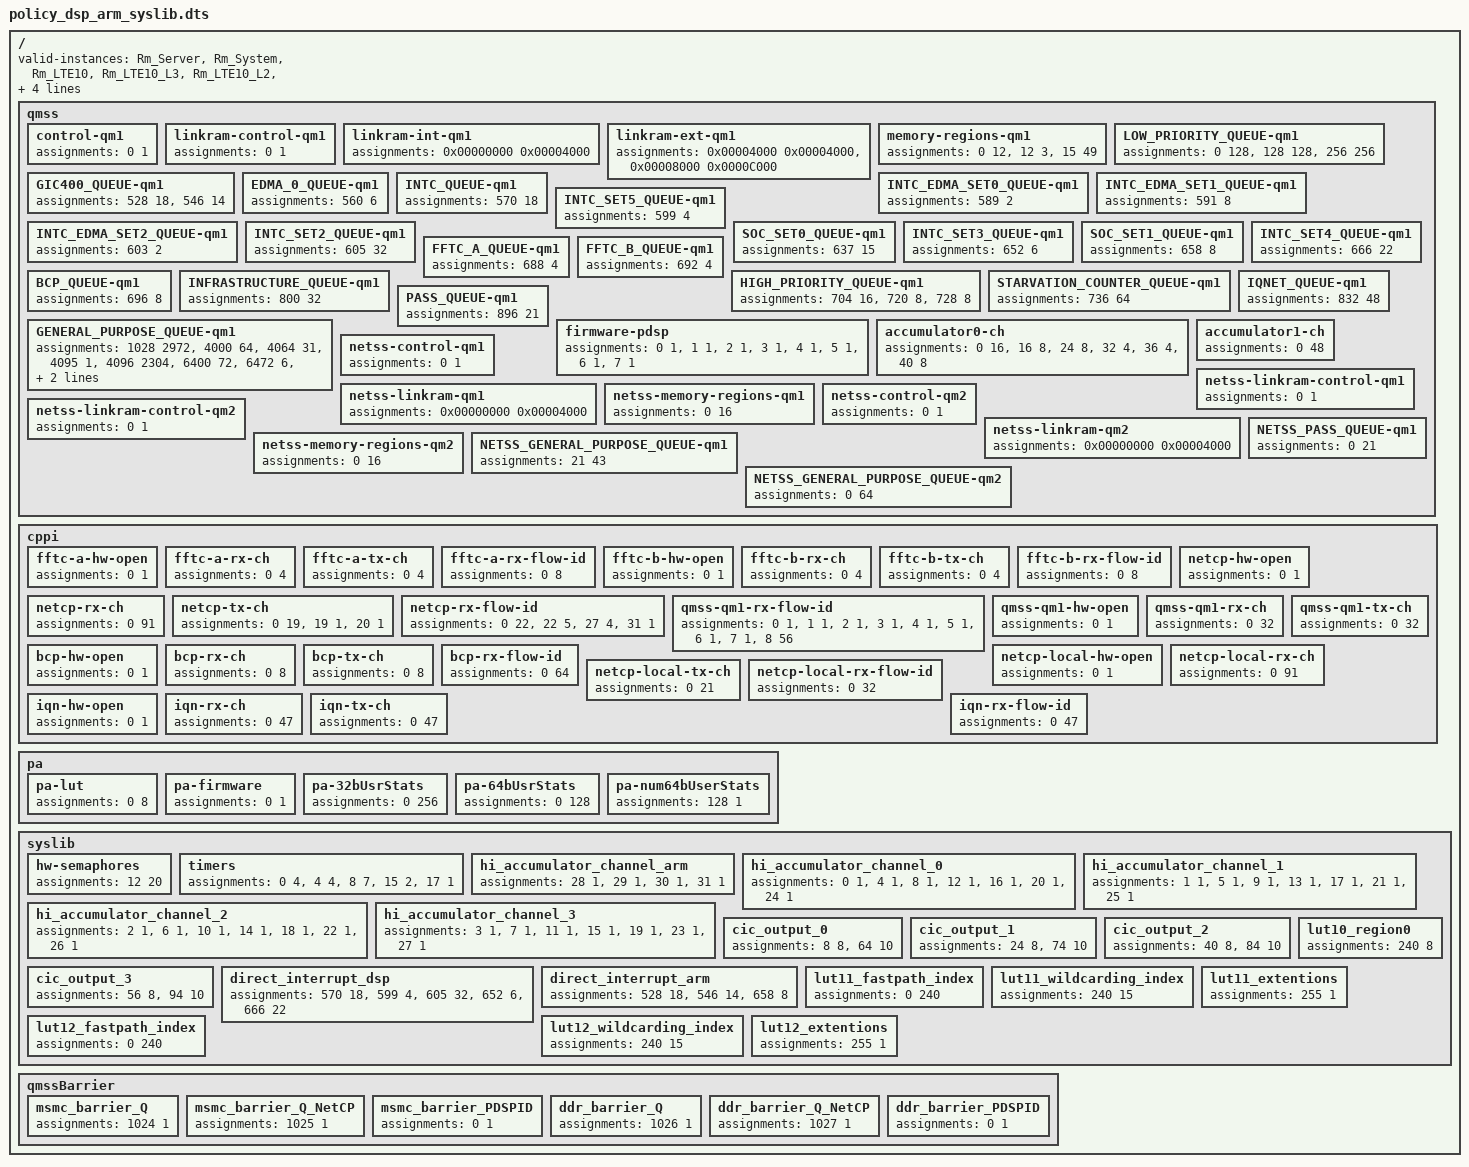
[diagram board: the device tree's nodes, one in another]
/dts-v1/;

/* Keystone II policy containing reserving resources used by Linux Kernel */

/ {
    /* Valid instance list contains instance names used within TI example projects
     * utilizing RM.  The list can be modified as needed by applications integrating
     * RM.  For an RM instance to be given permissions the name used to initialize it
     * must be present in this list */
    valid-instances = "Rm_Server",
                      "Rm_System",
                      "Rm_LTE10",
                      "Rm_LTE10_L3",
                      "Rm_LTE10_L2",
                      "Rm_LTE10_L2A",
                      "Rm_LTE10_L2B",
                      "Rm_LTE10_L1A",
                      "Rm_LTE10_L1B",
                      "Rm_LTE9A",
                      "Rm_LTE9A_L1",
                      "Rm_LTE9A_L2",
                      "Rm_LTE9B",
                      "Rm_LTE9B_L1",
                      "Rm_LTE9B_L2";
    qmss {
        control-qm1 {
            assignments = <0 1>, "iu = (*)";
        };

        linkram-control-qm1 {
            assignments = <0 1>, "(*)";             /* Used by Kernel */
        };

        linkram-int-qm1 {
            assignments = <0x00000000 0x00004000>, "iu = (*)";
        };
        linkram-ext-qm1 {
            /* linux provided 0x14000 descriptors of linking RAM but uses 0x4000 to 0x8000 */
            assignments = <0x00004000 0x00004000>, "(*)", /* used by Kernel */
                          <0x00008000 0x0000C000>, "iu = (*)";
        };

        memory-regions-qm1 {
            assignments = <0  12>, "iu = (*)",
                          <12 3>,  "(*)",             /* Used by Kernel */
                          <15 49>, "iu = (*)";
        };

        LOW_PRIORITY_QUEUE-qm1 {
            /* this is loosely coupled with accumulator-ch channels 32-47.  These queues are
             * just suggested to be paired with these channels, the accumulator can be sw
             * configured to use any queue */
            assignments = <0 128>,   "iu = (*)", /* suggested for channels 32-35 */
                          <128 128>, "     (*)", /* used by linux (accumulator-low-#); linux pairs these to channels 36-39 */
                          <256 256>, "iu = (*)"; /* suggested for channels 40-47 */
        };
        GIC400_QUEUE-qm1 {
            assignments = <528 18>,   "(*)",            /* Used by Kernel */
                          <546 14>,   "iu = (*)";
        };
        EDMA_0_QUEUE-qm1 {
            assignments = <560 6>, "iu = (*)";
        };
        INTC_QUEUE-qm1 {
            assignments = <570 18>, "iu = (*)";           /* Used by Kernel and DSP */
        };
        INTC_EDMA_SET0_QUEUE-qm1 {
            assignments = <589 2>,  "iu = (*)";
        };
        INTC_EDMA_SET1_QUEUE-qm1 {
            assignments = <591 8>,  "iu = (*)";
        };
        INTC_SET5_QUEUE-qm1 {
            assignments = <599 4>,  "iu = (*)";
        };
        INTC_EDMA_SET2_QUEUE-qm1 {
            assignments = <603 2>,  "iu = (*)";
        };
        INTC_SET2_QUEUE-qm1 {
            assignments = <605 32>, "iu = (*)";
        };
        SOC_SET0_QUEUE-qm1 {
            assignments = <637 15>, "iu = (*)";
        };
        INTC_SET3_QUEUE-qm1 {
            assignments = <652 6>,  "iu = (*)";
        };
        SOC_SET1_QUEUE-qm1 {
            assignments = <658 8>, "iu = (*)";
        };
        INTC_SET4_QUEUE-qm1 {
            assignments = <666 22>, "iu = (*)";
        };
        FFTC_A_QUEUE-qm1 {
            assignments = <688 4>, "iu = (*)";
        };
        FFTC_B_QUEUE-qm1 {
            assignments = <692 4>, "iu = (*)";
        };
        BCP_QUEUE-qm1 {
            assignments = <696 8>, "iu = (*)";
        };
        HIGH_PRIORITY_QUEUE-qm1 {
            /* this is loosely coupled with accumulator-ch channels 0-15.  These queues are
             * just suggested to be paired with these channels, the accumulator can be sw
             * configured to use any queue */
            assignments = <704 16>, "iu = (*)", /* suggested for channels 0-15 */
                          <720 8>,  "iu = (*)", /* Declared, but not used, by linux (accumulator-high.values). */
                          <728 8>,  "iu = (*)"; /* suggested for channels 24-31 */
        };
        STARVATION_COUNTER_QUEUE-qm1 {
            assignments = <736 64>, "iu = (*)";
        };
        INFRASTRUCTURE_QUEUE-qm1 {
            assignments = <800  32>,   "iu = (*)";
        };
        IQNET_QUEUE-qm1 {
            assignments = <832 48>, "iu = (*)";
        };
        PASS_QUEUE-qm1 {
            assignments = <896 21>, "iu = (*)";       /* used by both kernel and DSP */
        };
        GENERAL_PURPOSE_QUEUE-qm1 {
            assignments = /* First 4 queues are reserved for QMSS barrier */
                          /*<1024 4>,     "iu = (Rm_System)",*/
                          <1028 2972>,  "iu = (*)",
                          <4000 64>,    "(*)",       /* Used by Kernel */
                          <4064 31>,    "iu = (*)",
                          <4095 1>,     "iue = (*)",   /* Queues ending in 0xfff can't be used as return queue (hw reserved) */
                          <4096 2304>,  "iu = (*)",

                          /* 6400-6477 is taken by linux for qostree2, but DSP can transmit via "fastpath" queues */
                          <6400 72>,    "u = (*)",   /* qos queues for DSP (fastpath-best-effort, fastpath-hp, 4g-cos#, 3g-cos#, wifi-cos#) use (open by number) not init */
                          <6472 6>,     "(*)",       /* qos queues for linux (linux-best-effort, linux-cos#, linux-hp) - DSP can't use */
                          <6478 114>,   "(*)",       /* unconfigured QoS/Linux queues (qos-inputs-2) */

                          <6592 1408>,  "iu = (*)",

                          /* 8000-8191 is taken by linux for qostree but DSP can transmit via "fastpath" queues */
                          <8000 72>,    "u = (*)",   /* qos queues for DSP (fastpath-best-effort, fastpath-hp, 4g-cos#, 3g-cos#, wifi-cos#) use (open by number) not init */
                          <8072 6>,     "(*)",       /* qos queues for linux (linux-best-effort, linux-cos#, linux-hp) - DSP can't use */
                          <8078 114>,   "(*)";       /* unconfigured QoS/Linux queues (qos-inputs-1) */
                                                     /* note for q 8191: Queues ending in 0xfff can't be used as return queue (hw reserved) */
        };

        firmware-pdsp {
            assignments = <0 1>, "     (*)", /* pdsp0: accumulator 0 downloaded by linux */
                          <1 1>, "iu = (*)", /* pdsp1: for em scheduler if event machine is used (not downloaded by linux) */
                          <2 1>, "iu = (Rm_System)", /* pdsp2: for accumulator 1 on second intd (not downloaded by linux) */
                          <3 1>, "     (*)", /* pdsp3: qostree downloaded by linux */
                          <4 1>, "iu = (*)", /* pdsp4: for em scheduler if event machine is used (not downloaded by linux) */
                          <5 1>, "iu = (*)", /* pdsp5: for em scheduler if event machine is used (not downloaded by linux) */
                          <6 1>, "iu = (*)", /* pdsp6: for em router if event machine is used (not downloaded by linux) */
                          <7 1>, "     (*)"; /* pdsp7: qostree2 downloaded by linux */
        };
        accumulator0-ch { /* accumulator using first INTD */
            assignments = <0 16>, "iu = (*)",    /* high priority 0-15 available for everyone */
                          <16 8>, "iu = (*)",    /* declared but not used by linux, subject to change */
                          <24 8>, "iu = (*)",    /* last 8 high priority are used by event machine, available in non EM use case */
                          <32 4>, "iu = (*)",    /* first 4 low priority are used by event machine, available in non EM use case */
                          <36 4>, "     (*)",    /* next 4 low priority are used by linux (accumulator-low-#) */
                          <40 8>, "iu = (*)";    /* available for all */
        };
        accumulator1-ch { /* accumulator using second INTD */
            assignments = <0 48>, "iu = (*)";    /* linux doesn't use it */
        };

        netss-control-qm1 {
            assignments = <0 1>, "iu = (*)";
        };
        netss-linkram-control-qm1 {
            assignments = <0 1>, "iu = (*)";
        };
        netss-linkram-qm1 {
            assignments = <0x00000000 0x00004000>, "iu = (*)";
        };
        netss-memory-regions-qm1 {
            assignments = <0 16>, "iu = (*)";
        };

        netss-control-qm2 {
            assignments = <0 1>, "iu = (*)";
        };
        netss-linkram-control-qm2 {
            assignments = <0 1>, "iu = (*)";
        };
        netss-linkram-qm2 {
            assignments = <0x00000000 0x00004000>, "iu = (*)";
        };
        netss-memory-regions-qm2 {
            assignments = <0 16>, "iu = (*)";
        };

        NETSS_PASS_QUEUE-qm1 {
            assignments = <0 21>, "iu = (*)";
        };
        NETSS_GENERAL_PURPOSE_QUEUE-qm1 {
            assignments = <21 43>, "iu = (*)";
        };
        NETSS_GENERAL_PURPOSE_QUEUE-qm2 {
            assignments = <0 64>, "iu = (*)";
        };
    }; /* qmss */

    cppi {
        fftc-a-hw-open {
            assignments = <0 1>, "iu = (*)";
        };
        fftc-a-rx-ch {
            assignments = <0 4>, "iu = (*)";
        };
        fftc-a-tx-ch {
            assignments = <0 4>, "iu = (*)";
        };
        fftc-a-rx-flow-id {
            assignments = <0 8>, "iu = (*)";
        };   

        fftc-b-hw-open {
            assignments = <0 1>, "iu = (*)";
        };
        fftc-b-rx-ch {
            assignments = <0 4>, "iu = (*)";
        };
        fftc-b-tx-ch {
            assignments = <0 4>, "iu = (*)";
        };
        fftc-b-rx-flow-id {
            assignments = <0 8>, "iu = (*)";
        };   

        netcp-hw-open {
            assignments = <0 1>, "iu = (*)";
        };
        netcp-rx-ch {
            assignments = <0 91>, "     (*)"; /* initialized by kernel */
        };
        netcp-tx-ch {
            assignments = <0  19>, "     (*)", /* initialized by kernel, can directly open queuse */
                          <19  1>, "iu = (*)", /* SA channel.  Linux initializes, but some applications need to enable/disable on fly */
                          <20  1>, "     (*)"; /* initialized by kernel, can directly open queuse */

        };
        netcp-rx-flow-id {
            assignments = <0 22>, "iu = (*)", /* available */
                          <22 5>, "     (*)", /* used by kernel (netrx0, netrx1, netrx2, netrx3, crypto-rx0) */
                          <27 4>, "iu = (*)", /* available */
                          <31 1>, "(*)";      /* Used by kernel - parx */
        };

        /*****************************************************************************************
         * NOTE: The name proxy(s) for DSP-ARM communication reserves 2 sets of infrastructure
         * resources which are required used by the agent server in each realm.
         *
         * LTE9A RAT ARM Name Proxy resource usage
         *    Local Flow Id  0 :
         *    Rx Channel     0 :
         *    Tx Channel     1 :
         *
         * LTE9A RAT DSP Name Proxy resource usage
         *    Local Flow Id  1 :
         *    Rx Channel     1 :
         *    Tx Channel     0 :
         *
         * LTE9A RAT ARM Name Proxy resource usage
         *    Local Flow Id  2 :
         *    Rx Channel     2 :
         *    Tx Channel     3 :
         *
         * LTE9A RAT DSP Name Proxy resource usage
         *    Local Flow Id  3 :
         *    Rx Channel     3 :
         *    Tx Channel     2 :
         *
         * It is assumed that the name proxy in the DSP is executing in the L2 domain. If this is
         * not the case please change the RM client name accordingly.
         *
         * For the Release 10; the name proxy will execute on the DSP in the L1 domain. The L2 domain
         * whether it executes on DSP/ARM will also execute the name proxy. There could be 2 L2
         * domains L2A handling L1A and L2B handling L2B.
         *
         * The convention is that Flow Id 0, 2, 4, 6 are always used by the SYSLIB servers.
         * Flow Id 1, 3, 5, 7 are available to the applications.
         ********************************************************************************************/
        qmss-qm1-rx-flow-id {
            assignments = <0 1>,  "iu = (Rm_LTE9A Rm_LTE10)",
                          <1 1>,  "iu = (Rm_LTE9A_L2 Rm_LTE10_L1A)",
                          <2 1>,  "iu = (Rm_LTE9B Rm_LTE10)",
                          <3 1>,  "iu = (Rm_LTE9B_L2 Rm_LTE10_L1B)",
                          <4 1>,  "iu = (Rm_LTE10)",
                          <5 1>,  "iu = (Rm_LTE10_L2A)",
                          <6 1>,  "iu = (Rm_LTE10)",
                          <7 1>,  "iu = (Rm_LTE10_L2B)",
                          <8 56>, "iu = (*)";
        };
        qmss-qm1-hw-open {
            assignments = <0 1>, "iu = (*)";
        };
        qmss-qm1-rx-ch {
            assignments = <0 32>, "iu = (*)";
        };
        qmss-qm1-tx-ch {
            assignments = <0 32>, "iu = (*)";
        };

        bcp-hw-open {
            assignments = <0 1>, "iu = (*)";
        };
        bcp-rx-ch {
            assignments = <0 8>, "iu = (*)";
        };
        bcp-tx-ch {
            assignments = <0 8>, "iu = (*)";
        };
        bcp-rx-flow-id {
            assignments = <0 64>, "iu = (*)";
        };
        
        netcp-local-hw-open {
            assignments = <0 1>, "iu = (*)";
        };
        netcp-local-rx-ch {
            assignments = <0 91>, "iu = (*)";
        };
        netcp-local-tx-ch {
            assignments = <0 21>, "iu = (*)";
        };
        netcp-local-rx-flow-id {
            assignments = <0 32>, "iu = (*)";
        };

        iqn-hw-open {
            assignments = <0 1>, "iu = (*)";
        };
        iqn-rx-ch {
            assignments = <0 47>, "iu = (*)";
        };
        iqn-tx-ch {
            assignments = <0 47>, "iu = (*)";
        };
        iqn-rx-flow-id {
            assignments = <0 47>, "iu = (*)";
        };
    }; /* cppi */

    pa {
        pa-lut {
            assignments = <0 8>, "iu = (*)";
        };
        pa-firmware {
            assignments = <0 1>, "(*)"; /* linux downloads PA firmware */
        };
        pa-32bUsrStats {
            assignments = <0 256>, "iu = (*)";
        };
        pa-64bUsrStats {
            assignments = <0 128>, "iu = (*)";
        };
        pa-num64bUserStats {
            assignments = <128 1>, "iu = (*)";
        };
    }; /* pa */

    syslib {
        /*****************************************************************************
         * Hardware semaphores:
         *  - All hardware semaphores are assigned to all the RM instances
         *****************************************************************************/
        hw-semaphores {
            assignments = <12 20>, "iu = (*)";
        };

        /*****************************************************************************
         * Hardware timers:
         *  - Assign the hardware timers to the all RM instances.
         *  - Each DSP core executing BIOS will take 1 timer.
         *  - Timer 15 is taken up by the Linux kernel.
         *****************************************************************************/
        timers {
            assignments = <0  4>,  "     (*)", /* used by BIOS kernel on DSP cores */
                          <4  4>,  "     (*)", /* These are not available on K2L */
                          <8  7>,  "iu = (*)", /* available */
                          <15 2>,  "     (*)", /* used by kernel */
                          <17 1>,  "iu = (*)"; /* available */
        };

        /*****************************************************************************
         * High Priority accumulated channels:
         *  - Each core has 7 assigned channels each of which is available to all the
         *    RM instances.
         *  - ARM has 4 accumulated channels allocated for its use
         *****************************************************************************/
        hi_accumulator_channel_arm {
            assignments =   <28 1>, "iu = (*)",
                            <29 1>, "iu = (*)",
                            <30 1>, "iu = (*)",
                            <31 1>, "iu = (*)";
        };
        hi_accumulator_channel_0 {
            assignments =   <0  1>, "iu = (*)",
                            <4  1>, "iu = (*)",
                            <8  1>, "iu = (*)",
                            <12 1>, "iu = (*)",
                            <16 1>, "iu = (*)",
                            <20 1>, "iu = (*)",
                            <24 1>, "iu = (*)";
        };
        hi_accumulator_channel_1 {
            assignments =   <1  1>, "iu = (*)",
                            <5  1>, "iu = (*)",
                            <9  1>, "iu = (*)",
                            <13 1>, "iu = (*)",
                            <17 1>, "iu = (*)",
                            <21 1>, "iu = (*)",
                            <25 1>, "iu = (*)";
        };
        hi_accumulator_channel_2 {
            assignments =   <2  1>, "iu = (*)",
                            <6  1>, "iu = (*)",
                            <10 1>, "iu = (*)",
                            <14 1>, "iu = (*)",
                            <18 1>, "iu = (*)",
                            <22 1>, "iu = (*)",
                            <26 1>, "iu = (*)";
        };
        hi_accumulator_channel_3 {
            assignments =   <3  1>, "iu = (*)",
                            <7  1>, "iu = (*)",
                            <11 1>, "iu = (*)",
                            <15 1>, "iu = (*)",
                            <19 1>, "iu = (*)",
                            <23 1>, "iu = (*)",
                            <27 1>, "iu = (*)";
        };

        /*****************************************************************************
         * System Interrupt Mappings:
         *  - Each system interrupt on each is available to all RM instances.
         *****************************************************************************/
        cic_output_0 {
            assignments = <8  8>  , "iu = (*)",
                          <64 10> , "iu = (*)";
        };
        cic_output_1 {
            assignments = <24 8>  , "iu = (*)",
                          <74 10> , "iu = (*)";
        };
        cic_output_2 {
            assignments = <40 8>  , "iu = (*)",
                          <84 10> , "iu = (*)";
        };
        cic_output_3 {
            assignments = <56 8>  , "iu = (*)",
                          <94 10> , "iu = (*)";
        };

        /*****************************************************************************
         * Direct Interrupt Mappings:
         *  - On the DSP all the direct interrupt queues are available to all RM
         *    instances
         *  - On ARM however we need to be careful since the GIC queues are also used
         *    by the Linux kernel; so any changes in the GIC queue assignments would
         *    need to be aligned with the kernel DTB file also.
         *  - SOC-SET1 is shared but currently has been allocated to ARM
         *****************************************************************************/
        direct_interrupt_dsp {
            assignments = <570  18>  , "iu = (*)",
                          <599  4>   , "iu = (*)",
                          <605  32>  , "iu = (*)",
                          <652  6>   , "iu = (*)",
                          <666  22>  , "iu = (*)";
        };
        direct_interrupt_arm {
            assignments = <528  18> , "     (*)",    /* Used by the Linux kernel. */
                          <546  14> , "iu = (*)",
                          <658  8>  , "iu = (*)";
        };

        /*****************************************************************************
         * LUT1-0 entries for Ethernet Rules
         ****************************************************************************/
        lut10_region0 {
            assignments = <240 8>, "iu = (*)";
        };

        /*****************************************************************************
         * LUT1 entries
         * - The following section defines how LUT1 entries will be used in fast path
         *   creation
         * - There are 3 groups for both LUT1-1 and LUT1-2
         *   1. Normal Fast Path
         *   2. Wild Carding Fast Path
         *   3. LUT Extension
         *****************************************************************************/
        /* LUT1-1 */
        lut11_fastpath_index {
            assignments = <0 240>, "iu = (*)";
        };
        lut11_wildcarding_index {
            assignments = <240 15>, "iu = (*)";
        };
        lut11_extentions {
            assignments = <255 1>, "     (*)";    /* Reserved */
        };

        /* LUT1-2 */
        lut12_fastpath_index {
            assignments = <0 240>, "iu = (*)";
        };
        lut12_wildcarding_index {
            assignments = <240 15>, "iu = (*)";
        };
        lut12_extentions {
            assignments = <255 1>, "     (*)";    /* Reserved */
        };
    }; /* syslib */

    qmssBarrier {
        msmc_barrier_Q {
            assignments = <1024 1>, "iu = (Rm_System)";  /* QMSS MSMC Barrier Queues */
        };
        msmc_barrier_Q_NetCP {
            assignments = <1025 1>, "iu = (Rm_System)";  /* QMSS MSMC Barrier Queues */
        };
        msmc_barrier_PDSPID {
            assignments = <0 1>, "iu = (Rm_System)";    /* QMSS MSMC Barrier PDSP ID */
        };
        ddr_barrier_Q {
            assignments = <1026 1>, "iu = (Rm_System)";  /* QMSS DDR Barrier Queues */
        };
        ddr_barrier_Q_NetCP {
            assignments = <1027 1>, "iu = (Rm_System)";  /* QMSS DDR Barrier Queues */
        };
        ddr_barrier_PDSPID {
            assignments = <0 1>, "iu = (Rm_System)";    /* QMSS DDR Barrier PDSP ID */
        };
    }; /* qmssBarrier */

};
